# STM32WBA25xx register map
File version: 1.0
Registers are 32-bit, read-write, reset 0x0 unless marked. A register's access mark holds for its fields unless they carry their own. Offsets are from the block's base; [hi:lo] are bit positions; {n}, {i} and the like mark numbered series; 'fields as' and 'values as' point back to an identical list.

## GTZC_TZSC — Global TrustZone Controller
Base 0x40032400
0x00 CR — TZSC control register
  [0] LCK — GTZC Secure and privilege configurations lock
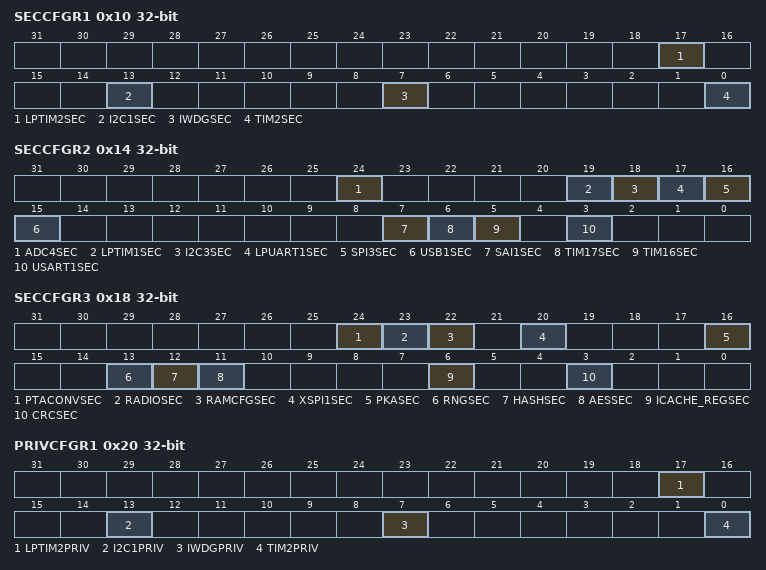
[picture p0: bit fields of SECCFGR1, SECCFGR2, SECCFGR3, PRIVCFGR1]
0x10 SECCFGR1 — TZSC secure configuration register 1
  [17] LPTIM2SEC — secure access mode for LPTIM2
  [13] I2C1SEC — secure access mode for I2C1
  [7] IWDGSEC — secure access mode for IWDG
  [0] TIM2SEC — secure access mode for TIM2
0x14 SECCFGR2 — TZSC secure configuration register 2
  [24] ADC4SEC — secure access mode for ADC4
  [19] LPTIM1SEC — secure access mode for LPTIM1
  [18] I2C3SEC — secure access mode for I2C3
  [17] LPUART1SEC — secure access mode for LPUART1
  [16] SPI3SEC — secure access mode for SPI3
  [15] USB1SEC — secure access mode for USB
  [7] SAI1SEC — secure access mode for SAI1
  [6] TIM17SEC — secure access mode for TIM17
  [5] TIM16SEC — secure access mode for TIM16
  [3] USART1SEC — secure access mode for USART1
0x18 SECCFGR3 — TZSC secure configuration register 3
  [24] PTACONVSEC — secure access mode for PTACONV
  [23] RADIOSEC — secure access mode for 2.4 GHz RADIO
  [22] RAMCFGSEC — secure access mode for RAMCFG
  [20] XSPI1SEC — secure access mode for XSPI1
  [16] PKASEC — secure access mode for PKA
  [13] RNGSEC — secure access mode for RNG
  [12] HASHSEC — secure access mode for HASH
  [11] AESSEC — secure access mode for AES
  [6] ICACHE_REGSEC — secure access mode for ICACHE_REG
  [3] CRCSEC — secure access mode for CRC
0x20 PRIVCFGR1 — TZSC privilege configuration register 1
  [17] LPTIM2PRIV — privileged access mode for LPTIM2
  [13] I2C1PRIV — privileged access mode for I2C1
  [7] IWDGPRIV — privileged access mode for IWDG
  [0] TIM2PRIV — privileged access mode for TIM2
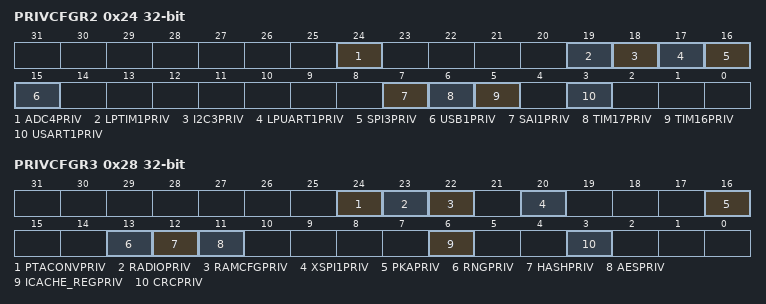
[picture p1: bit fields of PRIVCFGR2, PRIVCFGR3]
0x24 PRIVCFGR2 — TZSC privilege configuration register 2
  [24] ADC4PRIV — privileged access mode for ADC4
  [19] LPTIM1PRIV — privileged access mode for LPTIM1
  [18] I2C3PRIV — privileged access mode for I2C3
  [17] LPUART1PRIV — privileged access mode for LPUART1
  [16] SPI3PRIV — privileged access mode for SPI3
  [15] USB1PRIV — privileged access mode for USB
  [7] SAI1PRIV — privileged access mode for SAI1
  [6] TIM17PRIV — privileged access mode for TIM17
  [5] TIM16PRIV — privileged access mode for TIM16
  [3] USART1PRIV — privileged access mode for USART1
0x28 PRIVCFGR3 — TZSC privilege configuration register 3
  [24] PTACONVPRIV — privileged access mode for PTACONV
  [23] RADIOPRIV — privileged access mode for 2.4 GHz RADIO
  [22] RAMCFGPRIV — privileged access mode for RAMCFG
  [20] XSPI1PRIV — privileged access mode for XSPI1
  [16] PKAPRIV — privileged access mode for PKA
  [13] RNGPRIV — privileged access mode for RNG
  [12] HASHPRIV — privileged access mode for HASH
  [11] AESPRIV — privileged access mode for AES
  [6] ICACHE_REGPRIV — privileged access mode for ICACHE_REG
  [3] CRCPRIV — privileged access mode for CRC
0x40 MPCWM1ACFGR — TZSC memory 1 sub-region A watermark configuration register
0x44 MPCWM1AR — TZSC memory 1 sub-region A watermark register
0x48 MPCWM1BCFGR — TZSC memory 1 sub-region B watermark configuration register
0x4C MPCWM1BR — TZSC memory 1 sub-region B watermark register

## GTZC_MPCBB1
Base 0x40032C00
Same registers: GTZC_MPCBB2 0x40033000
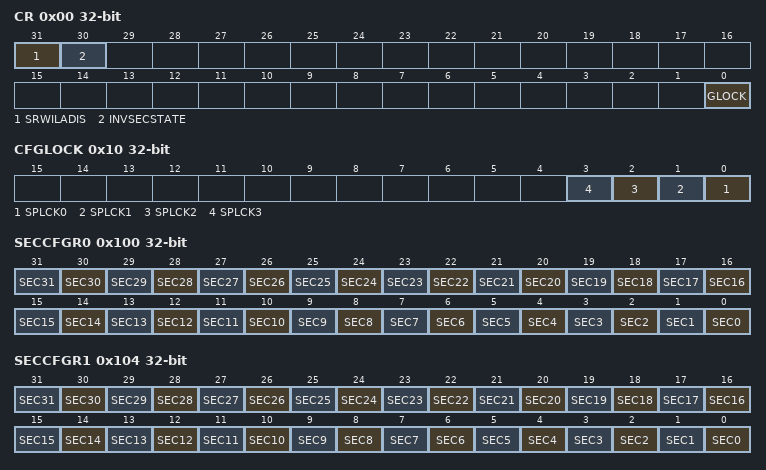
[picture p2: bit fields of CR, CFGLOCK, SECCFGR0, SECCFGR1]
0x00 CR — MPCBBx control register
  [31] SRWILADIS — secure read/write illegal access disable
  [30] INVSECSTATE — SRAM clocks security state
  [0] GLOCK — lock the control register of the MPCBB until next reset
0x10 CFGLOCK — MPCBBx lock register
  [n] SPLCK{n} (n=0..3) — Security/privilege configuration lock super-block {n}
0x100 SECCFGR0 — MPCBBx security configuration registers
  [n] SEC{n} (n=0..31) — Security configuration for block {n} in super block 0
0x104 SECCFGR1 — MPCBBx security configuration registers
  [n] SEC{n} (n=0..31) — Security configuration for block {n} in super block 1
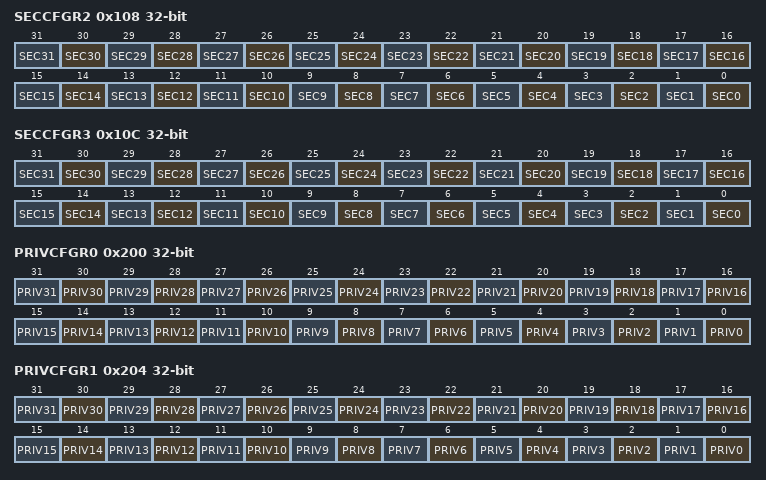
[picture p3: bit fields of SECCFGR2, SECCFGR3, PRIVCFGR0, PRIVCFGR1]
0x108 SECCFGR2 — MPCBBx security configuration registers
  fields as SECCFGR0
0x10C SECCFGR3 — MPCBBx security configuration registers
  fields as SECCFGR0
0x200 PRIVCFGR0 — MPCBBx privilege configuration registers
  [n] PRIV{n} (n=0..31) — Privileged configuration for block {n} in super block 0
0x204 PRIVCFGR1 — MPCBBx privilege configuration registers
  [n] PRIV{n} (n=0..31) — Privileged configuration for block {n} in super block 1
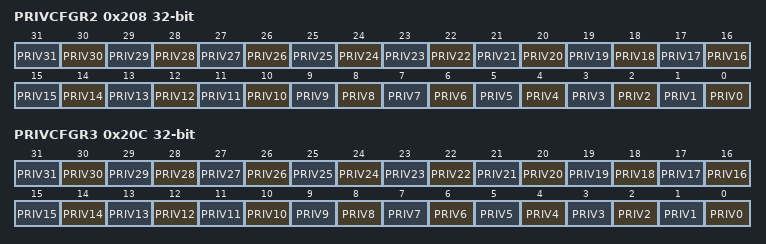
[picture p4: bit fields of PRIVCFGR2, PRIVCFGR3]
0x208 PRIVCFGR2 — MPCBBx privilege configuration registers
  fields as PRIVCFGR0
0x20C PRIVCFGR3 — MPCBBx privilege configuration registers
  fields as PRIVCFGR0
